# MCXN947_cm33_core0 register map
Vendor: nxp.com; File version: 1.0
CPU: CM33 r2p0, little endian, MPU, FPU, VTOR, 3 interrupt priority bits
Registers are 32-bit, read-write, reset 0x0 unless marked. A register's access mark holds for its fields unless they carry their own. Offsets are from the block's base; [hi:lo] are bit positions; lines under a group give offsets from that group; {n}, {i} and the like mark numbered series.

## FMU0TEST — FlashTest
Base 0x4004E000
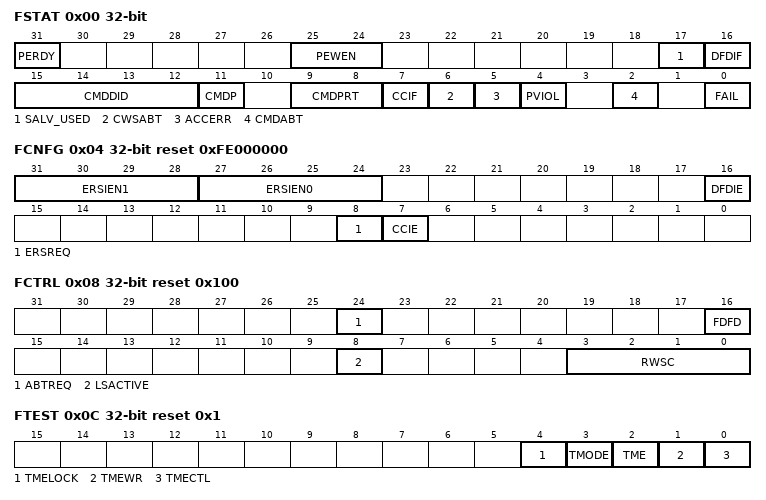
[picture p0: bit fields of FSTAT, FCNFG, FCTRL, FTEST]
0x00 FSTAT — Flash Status Register
  [31] PERDY — Program/Erase Ready Control/Status Flag
    0=zz1 (Program or sector erase command operation is not stalled); 1=zz2 (Program or sector erase command operation is stalled)
  [25:24] PEWEN — Program-Erase Write Enable Control
    0=zz3 (Writes are not enabled); 1=zz4 (Writes are enabled for one flash or IFR phrase (phrase programming, sector erase)); 2=zz5 (Writes are enabled for one flash or IFR page (page programming))
  [17] SALV_USED — Salvage Used for Erase operation
    0=zz7 (Salvage not used during the last operation); 1=zz8 (Salvage used during the last erase operation)
  [16] DFDIF ro — Double Bit Fault Detect Interrupt Flag
    0=zz9 (Double bit fault not detected during a valid flash read access from the FMC); 1=zz10 (Double bit fault detected (or FCTRL[FDFD] is set) during a valid flash read access from the FMC)
  [15:12] CMDDID ro — Command Domain ID
  [11] CMDP ro — Command Protection Status Flag
    0=zz11 (Command protection level and domain ID are stale); 1=zz12 (Command protection level (CMDPRT) and domain ID (CMDDID) are set)
  [9:8] CMDPRT ro — Command Protection Level
    0=zz13 (Secure, normal access); 1=zz14 (Secure, privileged access); 2=zz15 (Nonsecure, normal access); 3=zz16 (Nonsecure, privileged access)
  [7] CCIF write-1-clears — Command Complete Interrupt Flag
    0=zz17 (Flash command or initialization in progress); 1=zz18 (Flash command or initialization has completed)
  [6] CWSABT ro — Command Write Sequence Abort Flag
    0=zz19 (Command write sequence not aborted); 1=zz20 (Command write sequence aborted)
  [5] ACCERR write-1-clears — Command Access Error Flag
    0=zz21 (No access error detected); 1=zz22 (Access error detected)
  [4] PVIOL write-1-clears — Command Protection Violation Flag
    0=zz23 (No protection violation detected); 1=zz24 (Protection violation detected)
  [2] CMDABT ro — Command Abort Flag
    0=zz25 (No command abort detected); 1=zz26 (Command abort detected)
  [0] FAIL — Command Fail Flag
    0=zz27 (Error not detected); 1=zz28 (Error detected)
0x04 FCNFG reset 0xFE000000 — Flash Configuration Register
  [31:28] ERSIEN1 — Erase IFR Sector Enable - Block 1 (for dual block configs)
    0=zz29 (Block 1 IFR Sector X is protected from erase by ERSSCR command); 1=zz30 (Block 1 IFR Sector X is not protected from erase by ERSSCR command)
  [27:24] ERSIEN0 — Erase IFR Sector Enable - Block 0
    0=zz31 (Block 0 IFR Sector X is protected from erase by ERSSCR command); 1=zz32 (Block 0 IFR Sector X is not protected from erase by ERSSCR command)
  [16] DFDIE ro — Double Bit Fault Detect Interrupt Enable
    0=zz33 (Double bit fault detect interrupt disabled); 1=zz34 (Double bit fault detect interrupt enabled; an interrupt request is generated whenever the FSTAT[DFDIF] flag is set)
  [8] ERSREQ ro — Mass Erase (Erase All) Request
    0=zz35 (No request or request complete); 1=zz36 (Request to run the Mass Erase operation)
  [7] CCIE ro — Command Complete Interrupt Enable
    0=zz37 (Command complete interrupt disabled); 1=zz38 (Command complete interrupt enabled. An interrupt request is generated whenever the FSTAT[CCIF] flag is set.)
0x08 FCTRL reset 0x100 — Flash Control Register
  [24] ABTREQ ro — Abort Request
    0=zz39 (No request to abort a command write sequence); 1=zz40 (Request to abort a command write sequence)
  [16] FDFD ro — Force Double Bit Fault Detect
    0=zz41 (FSTAT[DFDIF] sets only if a double bit fault is detected during a valid flash read access from the FMC); 1=zz42 (FSTAT[DFDIF] sets during any valid flash read access from the FMC; an interrupt request is generated if the DFDIE bit is set)
  [8] LSACTIVE — Low Speed Active Mode
    0=zz43 (Full speed active mode requested); 1=zz44 (Low speed active mode requested)
  [3:0] RWSC — Read Wait-State Control
    0=zz45 (no additional wait-states are added (single cycle access)); 1=zz46 (1 additional wait-state is added); {v}=zz{v+45} ({v} additional wait-states are added) (v=2..15)
0x0C FTEST ro reset 0x1 — Flash Test Register
  [4] TMELOCK — Test Mode Entry Lock
    0=zz61 (FTEST register not locked from accepting writes); 1=zz62 (FTEST register locked from accepting writes)
  [3] TMODE — Test Mode Status
    0=zz63 (Test mode not active); 1=zz64 (Test mode active)
  [2] TME — Test Mode Entry
    0=zz65 (Test mode entry not requested); 1=zz66 (Test mode entry requested)
  [1] TMEWR — Test Mode Entry Writable
    0=zz67 (TME bit is not writable); 1=zz68 (TME bit is writable)
  [0] TMECTL — Test Mode Entry Control
    0=zz69 (FTEST register always reads 0 and writes to FTEST are ignored); 1=zz70 (FTEST register is readable and can be written to enable writability of TME)
0x10 FCCOB0 — Flash Command Control 0 Register
  [7:0] CMDCODE — Command code
0x14 FCCOB1 — Flash Command Control 1 Register
  [7:0] CMDOPT — Command options
0x18 FCCOB2 — Flash Command Control 2 Register
  [31:0] CMDADDR — Command starting address
0x1C FCCOB3 — Flash Command Control 3 Register
  [31:0] CMDADDRE — Command ending address
{0x10+4i} FCCOB{i} (i=4..7) — Flash Command Control {i} Register
  [31:0] CMDDATA{i-4} — Command data word {i-4}
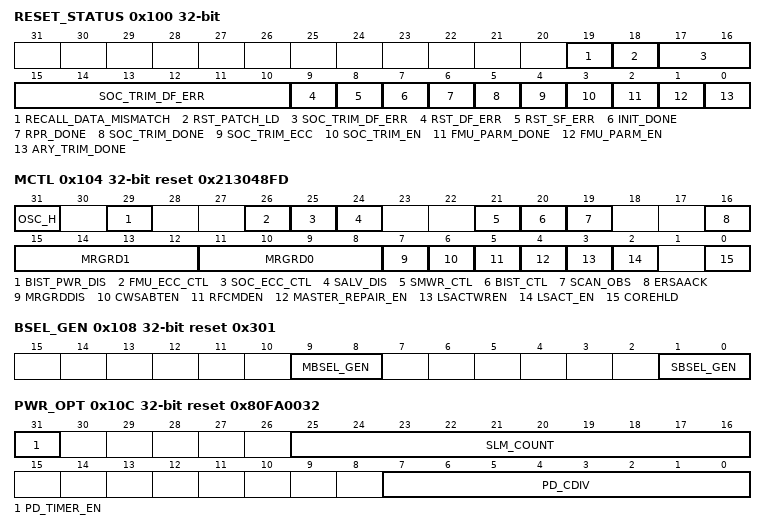
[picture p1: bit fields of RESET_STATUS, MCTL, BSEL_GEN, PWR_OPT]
0x100 RESET_STATUS — FMU Initialization Tracking Register
  [19] RECALL_DATA_MISMATCH
    0=zz71 (Data read towards end of reset matched data read for Recall); 1=zz72 (Data read towards end of reset did not match data read for recall)
  [18] RST_PATCH_LD — Reset Patch Required
    0=zz73 (No patch required to be loaded during reset); 1=zz74 (Patch loaded during reset)
  [17:10] SOC_TRIM_DF_ERR — ECC Double Fault during load of SoC Trim phrases
  [9] RST_DF_ERR — ECC Double Fault during Reset Recovery
    0=zz75 (No double-bit faults detected during initialization); 1=zz76 (Double-bit ECC fault was detected during initialization)
  [8] RST_SF_ERR — ECC Single Fault during Reset Recovery
    0=zz77 (No single-bit faults detected during initialization); 1=zz78 (At least one single ECC fault was detected during initialization)
  [7] INIT_DONE — Initialization Done
    0=zz79 (All initialization steps did not complete); 1=zz80 (All initialization steps completed)
  [6] RPR_DONE — Array Repair Complete
    0=zz81 (Repair registers have not been loaded); 1=zz82 (Repair registers have been loaded)
  [5] SOC_TRIM_DONE — SoC Trim Complete
    0=zz83 (SoC Trim registers have not been updated); 1=zz84 (All SoC Trim registers have been updated)
  [4] SOC_TRIM_ECC — Status of the C0DE_C0DEh check for enabling ECC decoder during reads of SoC trim settings
    0=zz85 (C0DE_C0DEh check failed); 1=zz86 (C0DE_C0DEh check passed)
  [3] SOC_TRIM_EN — Status of the C0DE_C0DEh check to enable loading of the SoC trim settings
    0=zz87 (C0DE_C0DEh check not attempted); 1=zz88 (C0DE_C0DEh check completed)
  [2] FMU_PARM_DONE — FMU Register Load Complete
    0=zz89 (FMU registers have not been loaded); 1=zz90 (FMU registers have been loaded)
  [1] FMU_PARM_EN — Status of the C0DE_C0DEh check to enable loading of the FMU parameters
    0=zz91 (C0DE_C0DEh check not attempted); 1=zz92 (C0DE_C0DEh check completed)
  [0] ARY_TRIM_DONE — Array Trim Complete
    0=zz93 (Recall register load operation has not been completed); 1=zz94 (Recall register load operation has completed)
0x104 MCTL reset 0x213048FD — FMU Control Register
  [31] OSC_H — Oscillator control
    0=zz95 (Use APB clock); 1=zz96 (Use a known fixed-frequency clock, e.g. 12 MHz)
  [29] BIST_PWR_DIS — BIST Power Mode Disable
    0=zz97 (BIST DFT logic has full control of SLM and LVE when BIST is enabled (including during commands)); 1=zz98 (BIST DFT logic has no control of SLM and LVE; power mode RTL is in complete control of SLM and LVE values)
  [26] FMU_ECC_CTL — FMU ECC Control
    0=zz99 (ECC is enabled for FMU program operations); 1=zz100 (ECC is disabled for FMU program operations)
  [25] SOC_ECC_CTL — SOC ECC Control
    0=zz101 (ECC is enabled for SOC read access); 1=zz102 (ECC is disabled for SOC read access)
  [24] SALV_DIS — Salvage Disable
    0=zz103 (Salvage enabled (ECC used during erase verify)); 1=zz104 (Salvage disabled (ECC not used during erase verify))
  [21] SMWR_CTL — SMWR IP Control
    0=zz105 (SMWR IP disabled); 1=zz106 (SMWR IP enabled)
  [20] BIST_CTL — BIST IP Control
    0=zz107 (BIST IP disabled); 1=zz108 (BIST IP enabled)
  [19] SCAN_OBS — Scan Observability Control
    0=zz109 (Normal functional behavior); 1=zz110 (Enables observation of signals that may otherwise be ATPG untestable)
  [16] ERSAACK — Mass Erase (Erase All) Acknowledge
    0=zz111 (Mass Erase operation is not active (operation has completed or has not started)); 1=zz112 (Mass Erase operation is active (controller acknowledges that the soc_ersall_req input is asserted and will continue with the operation))
  [15:12] MRGRD1 — Margin Read Setting for Erase
  [11:8] MRGRD0 — Margin Read Setting for Program
  [7] MRGRDDIS — Margin Read Disable
    0=zz113 (Margin Read Settings are enabled); 1=zz114 (Margin Read Settings are disabled)
  [6] CWSABTEN — Command Write Sequence Abort Enable
    0=zz115 (CWS abort feature is disabled); 1=zz116 (CWS abort feature is enabled)
  [5] RFCMDEN — RF Active Command Enable Control
    0=zz117 (Flash commands blocked (CCIF not writable)); 1=zz118 (Flash commands allowed)
  [4] MASTER_REPAIR_EN — Master Repair Enable
    0=zz119 (Repair disabled); 1=zz120 (Repair enable determined by bit 0 of each REPAIR register)
  [3] LSACTWREN — LSACTIVE Write Enable
    0=zz121 (Unrestricted write access allowed); 1=zz122 (Write access while CMP set must match CMDDID and CMDPRT)
  [2] LSACT_EN — LSACTIVE Feature Enable
    0=zz123 (LSACTIVE feature disabled completely: FCTRL[LSACTIVE] is forced low and no longer writable, LVE cannot assert at the TSMC array interface.); 1=zz124 (LSACTIVE feature fully enabled and controllable by SoC and internal UINT SM.)
  [0] COREHLD — Core Hold
    0=zz125 (CPU access is allowed); 1=zz126 (CPU access must be blocked)
0x108 BSEL_GEN ro reset 0x301 — FMU Block Select Generation Register
  [9:8] MBSEL_GEN — Generated MBSEL
  [1:0] SBSEL_GEN — Generated SBSEL
0x10C PWR_OPT reset 0x80FA0032 — Power Mode Options Register
  [31] PD_TIMER_EN — Power Down BIST Timer Enable
    0=zz127 (BIST timer is not triggered during Power Down recovery); 1=zz128 (BIST timer is triggered during Power Down recovery (default behavior))
  [25:16] SLM_COUNT — Sleep Recovery Timer Count
  [7:0] PD_CDIV — Power Down Clock Divider Setting
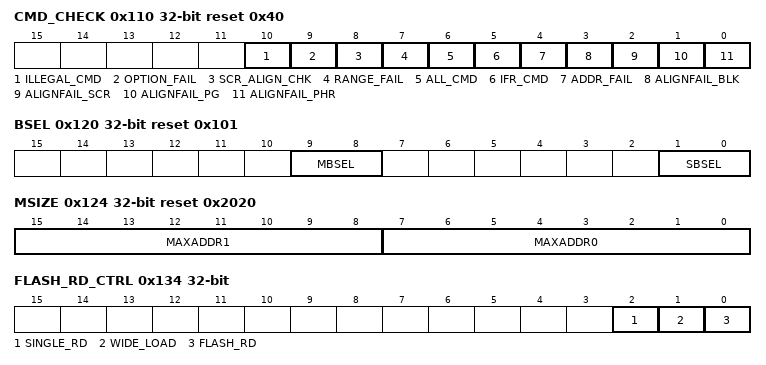
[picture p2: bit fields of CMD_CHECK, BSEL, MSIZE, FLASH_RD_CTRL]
0x110 CMD_CHECK ro reset 0x40 — FMU Command Check Register
  [10] ILLEGAL_CMD — Illegal Command
    0=zz129 (Command is legal); 1=zz130 (Command is illegal)
  [9] OPTION_FAIL — Option Check Fail
    0=zz131 (Option check passes for read command or command is not a read command); 1=zz132 (Option check fails for read command)
  [8] SCR_ALIGN_CHK — Sector Alignment Check
    0=zz133 (No sector alignment check); 1=zz134 (Sector alignment check)
  [7] RANGE_FAIL — Address Range Fail
    0=zz135 (The address range is valid); 1=zz136 (The address range is invalid)
  [6] ALL_CMD — All Blocks Command
    0=zz137 (The command operates on a single flash block); 1=zz138 (The command operates on all flash blocks)
  [5] IFR_CMD — IFR Command
    0=zz139 (The command operates on a main flash address); 1=zz140 (The command operates on an IFR address)
  [4] ADDR_FAIL — Address Fail
    0=zz141 (The address is within the flash or IFR address space); 1=zz142 (The address is outside the flash or IFR address space)
  [3] ALIGNFAIL_BLK — Block Alignment Fail
    0=zz143 (The address is block-aligned); 1=zz144 (The address is not block-aligned)
  [2] ALIGNFAIL_SCR — Sector Alignment Fail
    0=zz145 (The address is sector-aligned); 1=zz146 (The address is not sector-aligned)
  [1] ALIGNFAIL_PG — Page Alignment Fail
    0=zz147 (The address is page-aligned); 1=zz148 (The address is not page-aligned)
  [0] ALIGNFAIL_PHR — Phrase Alignment Fail
    0=zz149 (The address is phrase-aligned); 1=zz150 (The address is not phrase-aligned)
0x120 BSEL reset 0x101 — FMU Block Select Register
  [9:8] MBSEL — Master Block Select
  [1:0] SBSEL — Slave Block Select
0x124 MSIZE reset 0x2020 — FMU Memory Size Register
  [15:8] MAXADDR1 — Size of Flash Block 1
  [7:0] MAXADDR0 — Size of Flash Block 0
0x128 FLASH_RD_ADD — Flash Read Address Register
  [31:0] FLASH_RD_ADD — Flash Read Address
0x130 FLASH_STOP_ADD — Flash Stop Address Register
  [31:0] FLASH_STOP_ADD — Flash Stop Address
0x134 FLASH_RD_CTRL — Flash Read Control Register
  [2] SINGLE_RD — Single Flash Read
    0=zz151 (Normal UINT operation); 1=zz152 (UINT configured for single cycle reads)
  [1] WIDE_LOAD — Wide Load Enable
    0=zz153 (Wide load mode disabled (default)); 1=zz154 (Wide load mode enabled)
  [0] FLASH_RD — Flash Read Enable
    0=zz155 (Manual flash read not enabled.(default)); 1=zz156 (Manual flash read enabled)
0x138 MM_ADDR — Memory Map Address Register
  [31:0] MM_ADDR — Memory Map Address
0x140 MM_WDATA — Memory Map Write Data Register
  [31:0] MM_WDATA — Memory Map Write Data
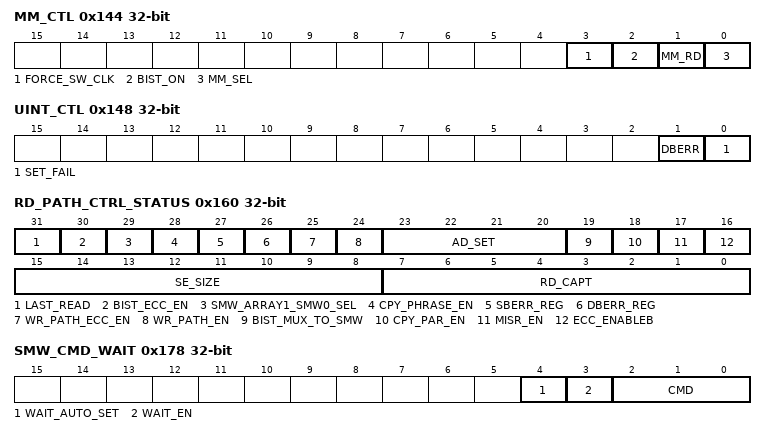
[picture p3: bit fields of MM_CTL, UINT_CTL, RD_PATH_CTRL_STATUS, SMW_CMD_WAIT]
0x144 MM_CTL — Memory Map Control Register
  [3] FORCE_SW_CLK — Force Switch Clock
    0=zz157 (Switch clock not forced on (gated normally)); 1=zz158 (Switch clock forced on)
  [2] BIST_ON
    0=zz159 (BIST enable not forced by user interface); 1=zz160 (BIST enable control by user interface)
  [1] MM_RD — Register R/W Control
    0=zz161 (Write to register); 1=zz162 (Read register)
  [0] MM_SEL — Register Access Enable
0x148 UINT_CTL — User Interface Control Register
  [1] DBERR — Double-Bit ECC Fault Detect
    0=zz163 (No double-bit fault detected during UINT-driven read sequence); 1=zz164 (Double-bit fault detected during UINT-driven read sequence)
  [0] SET_FAIL — Set Fail On Exit
    0=zz165 (FAIL flag should not be set on command exit (no failure detected)); 1=zz166 (FAIL flag should be set on command exit)
{0x14C+4i} RD_DATA{i} (i=0..3) — Read Data {i} Register
  [31:0] RD_DATA{i} — Read Data {i}
0x15C PARITY
  [8:0] PARITY — Read data [136:128]
0x160 RD_PATH_CTRL_STATUS — Read Path Control and Status Register
  [31] LAST_READ
    0=zz167 (Latest read not last in multi-address operation); 1=zz168 (Latest read last in multi-address operation)
  [30] BIST_ECC_EN — BIST ECC Enable
    0=zz169 (ECC correction disabled); 1=zz170 (ECC correction enabled)
  [29] SMW_ARRAY1_SMW0_SEL
    0=zz171 (Select block 0); 1=zz172 (Select block 1)
  [28] CPY_PHRASE_EN — Copy Phrase Enable
    0=zz173 (Copy Flash read data disabled); 1=zz174 (Copy Flash read data enabled)
  [27] SBERR_REG ro — Single-Bit Error
    0=zz175 (Single-bit fault not detected); 1=zz176 (Single-bit fault detected on previous UINT flash read)
  [26] DBERR_REG ro — Double-Bit Error
    0=zz177 (Double-bit fault not detected); 1=zz178 (Double-bit fault detected on previous UINT flash read)
  [25] WR_PATH_ECC_EN — Write Path ECC Enable
    0=zz179 (ECC encoding disabled); 1=zz180 (ECC encoding enabled)
  [24] WR_PATH_EN — Write Path Enable
    0=zz181 (Writes to BIST setting registers driven by MM_WDATA); 1=zz182 (Writes to BIST setting registers driven by SMW_DIN)
  [23:20] AD_SET — Multi-Cycle Address Setup Time
  [19] BIST_MUX_TO_SMW
    0=zz183 (BIST drives fields); 1=zz184 (SMW registers drive fields)
  [18] CPY_PAR_EN — Copy Parity Enable
    0=zz185 (Copy parity disabled); 1=zz186 (Copy parity enabled)
  [17] MISR_EN — MISR Enable
    0=zz187 (MISR option disabled (default)); 1=zz188 (MISR option enabled)
  [16] ECC_ENABLEB — ECC Decoder Control
    0=zz189 (ECC decoder enabled (default)); 1=zz190 (ECC decoder disabled)
  [15:8] SE_SIZE — SE Clock Periods
  [7:0] RD_CAPT — Read Capture Clock Periods
{0x164+4i} SMW_DIN{i} (i=0..3)
0x174 SMW_ADDR — SMW Address Register
  [31:0] SMW_ADDR — SMW Address
0x178 SMW_CMD_WAIT — SMW Command and Wait Register
  [4] WAIT_AUTO_SET — SMW Wait Auto Set
  [3] WAIT_EN — SMW Wait Enable
    0=zz191 (Wait feature disabled); 1=zz192 (Wait feature enabled)
  [2:0] CMD — SMW Command
    0=zz193 (IDLE); 1=zz194 (ABORT); 2=zz195 (SME2 to one-shot mass erase); 3=zz196 (SME3 to sector erase on selected array); 4=zz197 (SMP1 to program phrase or page on selected array with shot disabled on previously programmed bit); 6=zz199 (SMP2 to program phrase or page on selected array to repair cells of weak program after power loss)
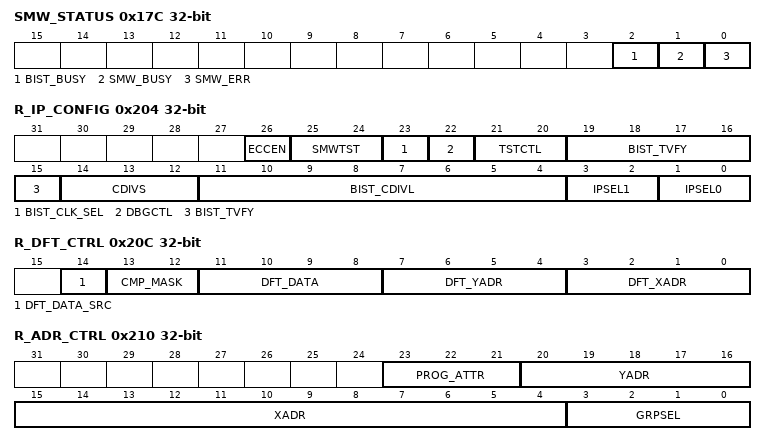
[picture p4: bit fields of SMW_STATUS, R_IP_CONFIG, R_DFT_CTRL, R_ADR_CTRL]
0x17C SMW_STATUS ro
  [2] BIST_BUSY
    0=zz201 (BIST Command not active); 1=zz202 (BIST Command is active)
  [1] SMW_BUSY
    0=zz203 (SMW command not active); 1=zz204 (SMW command is active)
  [0] SMW_ERR — SMW Error
    0=zz205 (Error not detected); 1=zz206 (Error detected)
{0x180+0x10*i} SOCTRIM{i}_0 reset 0xFFFFFFFF (i=0..7) — SoC Trim Phrase {i} Word 0 Register
  [31:0] TRIM{i}_0
{0x184+0x10*i} SOCTRIM{i}_1 reset 0xFFFFFFFF (i=0..7) — SoC Trim Phrase {i} Word 1 Register
  [31:0] TRIM{i}_1
{0x188+0x10*i} SOCTRIM{i}_2 reset 0xFFFFFFFF (i=0..7) — SoC Trim Phrase {i} Word 2 Register
  [31:0] TRIM{i}_2
{0x18C+0x10*i} SOCTRIM{i}_3 reset 0xFFFFFFFF (i=0..7) — SoC Trim Phrase {i} Word 3 Register
  [31:0] TRIM{i}_3
0x204 R_IP_CONFIG — BIST Configuration Register
  [26] ECCEN — BIST ECC Control
    0=zz207 (Default mode (no ECC encode or decode)); 1=zz208 (Enable ECC encode/decode)
  [25:24] SMWTST — SMWR DOUT Function Control
    0=zz209 (Default); 1=zz210 (Enable SMWR self-test mode, DOUT from macro will be forced to all 0); 2=zz211 (Enable SMWR self-test mode, DOUT from macro will be forced to all 1)
  [23] BIST_CLK_SEL — BIST Clock Select
  [22] DBGCTL — Debug feature control
    0=zz213 (Default); 1=zz214 (Enable debug feature to collect failure address and data.)
  [21:20] TSTCTL — BIST self-test control
    0=zz215 (Default, disable both BIST self-test and MISR); 1=zz216 (Enable BIST self-test mode DOUT from macro will be forced to '0', and disable MISR.); 2=zz217 (Enable MISR); 3=zz218 (Enable both BIST self-test mode and MISR)
  [19:15] BIST_TVFY — Timer adjust for verify
  [14:12] CDIVS — Number of clock cycles to generate short pulse
  [11:4] BIST_CDIVL — Clock Divide Scalar for Long Pulse
  [3:2] IPSEL1 — Block 1 Select Control
    0=zz219 (Unselect block 1); 1=zz220 (not used, reserved); 2=zz221 (Enable block 1 test, repair off (default)); 3=zz222 (Enable block 1 test, repair on)
  [1:0] IPSEL0 — Block 0 Select Control
    0=zz223 (Unselect block 0); 1=zz224 (not used, reserved); 2=zz225 (Enable block 0 test, repair off (default)); 3=zz226 (Enable block 0 test, repair on)
0x208 R_TESTCODE — BIST Test Code Register
  [5:0] TESTCODE — Used to store test code information before running TMR-RST/TMRSET BIST command
0x20C R_DFT_CTRL — BIST DFT Control Register
  [14] DFT_DATA_SRC — DFT Data Source
    0=zz227 ({R_DATA_CTRL0,R_DATA_CTRL_EX[2:0],R_DATA_CTRL0,R_DATA_CTRL_EX[2:0],R_DATA_CTRL0,R_DATA_CTRL_EX[2:0],R_DATA_CTRL0} is used); 1=zz228 ({R_DATA_CTRL3,R_DATA_CTRL2_EX[2:0],R_DATA_CTRL2,R_DATA_CTRL1_EX[2:0],R_DATA_CTRL1,R_DATA_CTRL_EX[2:0],R_DATA_CTRL0} is used)
  [13:12] CMP_MASK — Data Compare Mask
    0=zz229 (Expected data is compared to DOUT); 1=zz230 (Expected data (only 0s are considered) are compared to DOUT); 2=zz231 (Expected data (only 1s are considered) are compared to DOUT)
  [11:8] DFT_DATA — DFT Data Pattern
    0=zz232 (CKBD pattern. For READ operations only, compare DOUT with checkerboard data pattern for each read cycle.); 1=zz233 (ICKBD pattern. For READ operations only, compare DOUT with inverse checkerboard data pattern for each read cycle.); 2=zz234 (Diagonal pattern. Used for READ operations only, compare DOUT to diagonal pattern.); 3=zz235 (Fixed data pattern. For READ operations, comparison to DOUT for selected groups; refer to R_ADR_CTRL[GRPSEL] for modules with multiple groups.); 4=zz236 (Random data pattern which will be generated based on the initial seed set in R_DATA; for READ operations, used for DOUT comparison of selected groups. For PROG operations, used to control DIN of selected groups.); 5=zz237 (DOUT based pattern. For READ operations only, DOUT of selected group will be latched in R_DATA. If more than one group is selected in R_ADR_CTRL[GRPSEL], the group with the lower index will be latched.); 6=zz238 (R_DATA based pattern. For READ operations, expected DOUT value of selected groups equals to R_DATA when XADR[0]==YADR[0] or ~R_DATA when XADR[0]!=YADR[0]. For PROG operations, DIN of selected groups equals R_DATA when XADR[0]==YADR[0] or ~R_DATA when XADR[0]!=YADR[0].); 7=zz239 (SCAN-IO pattern. For READ operations, control expected DOUT value of selected groups to SCAN-IO data pattern. For PROG operations, control DIN of selected groups to SCAN-IO data pattern.); 8=zz240 (REPAIR set. For PROG operation to IFR1(7,1) and IFR1(7,2), R_REPAIR0_0 and R_REPAIR0_1 or R_REPAIR1_0 and R_REPAIR1_1 will control DIN. For READ operation on IFR1(7,1) and IFR1(7,2), DOUT will be compared against R_REPAIR0_0 and R_REPAIR0_1 or R_REPAIR1_0 andR_REPAIR1_1. When this option is selected, only one flash block can be selected.); 9=zz241 (REPAIR load. For READ operation only, DOUT from IFR1(7,1) and IFR1(7,2) is loaded to R_REPAIR0 and R_REPAIR1.)
  [7:4] DFT_YADR — DFT YADR Pattern
    0=zz242 (YADR fixed, no change at all); 1=zz243 (YADR for ICKBD. For PROG and READ operations, YADR changed to generate inverse checkerboard pattern.); 2=zz244 (YADR for CKBD. For PROG and READ operations, YADR changed to generate checkerboard pattern.); 3=zz245 (YADR increased by 1. For READ operations, YADR increased by 1 after each read cycle. For PROG operations, YADR increased by 1 after YE falls.); 4=zz246 (YADR increased for diagonal. For PROG-DIAGONAL operation, YADR is increased to create diagonal pattern.); 5=zz247 (YADR inversed. YADR is inversed after reading one word or after programming one word when YE falls.); 6=zz248 (YADR[0] inversed. YADR[0] is inversed after reading one word or after programming one word when YE falls.); 7=zz249 (YADR increased by 1 after last row. For READ operations only, YADR is increased by 1 after XADR reaches last row.); 8=zz250 (YADR decreased by 1. For READ operations only, YADR is decreased by 1 after each read cycle.); 9=zz251 (YADR decreased by 1 after first row. For READ operations only, YADR is decreased by 1 after XADR decreases to 0.)
  [3:0] DFT_XADR — DFT XADR Pattern
    0=zz252 (XADR fixed, no change at all); 1=zz253 (XADR increased by 1 after row. For READ operation, XADR increases by 1 after reading the last word of row. For PROG operation, XADR increases by 1 after NVSTR falls.); 2=zz254 (XADR increased for diagonal. For PROG-DIAGONAL operation, XADR is increased to create diagonal pattern.); 3=zz255 (XADR increased by sector. During ERASE operation, XADR increased by number of rows in a sector when NVSTR falls.); 4=zz256 (XADR inversed. XADR is inversed after reading one word or after programming one row when NVSTR falls.); 5=zz257 (XADR increased by 2 after row. For READ operation, XADR is increased by 2 after reading the last word of a row. For PROG operation, XADR is increased by 2 when NVSTR falls.); 6=zz258 (XADR[0] inversed. XADR[0] is inversed after reading one word or after programming one row when NVSTR falls.); 7=zz259 (XADR increased by 1. For READ operations only, XADR increased by 1 after each read cycle.); 8=zz260 (XADR decreased by 1 after row. For READ operations only, XADR is decreased by 1 after YADR decreases to 0.); 9=zz261 (XADR decreased by 1. For READ operations only, XADR is decreased by 1 after each read cycle.)
0x210 R_ADR_CTRL — BIST Address Control Register
  [23:21] PROG_ATTR — Program Attribute
    0=zz262 (One YE pulse will program one data slice group); 1=zz263 (One YE pulse will program two data slice groups); 2=zz264 (One YE pulse will program three data slice groups (reserved)); 3=zz265 (One YE pulse will program four data slice groups); 4=zz266 (One YE pulse will program five data slice groups (reserved)); 5=zz267 (One YE pulse will program six data slice groups (reserved)); 6=zz268 (One YE pulse will program seven data slice groups (reserved)); 7=zz269 (One YE pulse will program eight data slice groups (reserved))
  [20:16] YADR — BIST YADR
  [15:4] XADR — BIST XADR
  [3:0] GRPSEL — Data Group Select
    0=zz270 (Select no data); 1=zz271 (Select data slice [34:0]); 2=zz272 (Select data slice [69:35]); 4=zz273 (Select data slice [104:70]); 8=zz274 (Select data slice [136:105]); 15=zz275 (Select data [136:0])
0x214 R_DATA_CTRL0 — BIST Data Control 0 Register
  [31:0] DATA0 — BIST Data 0 Low
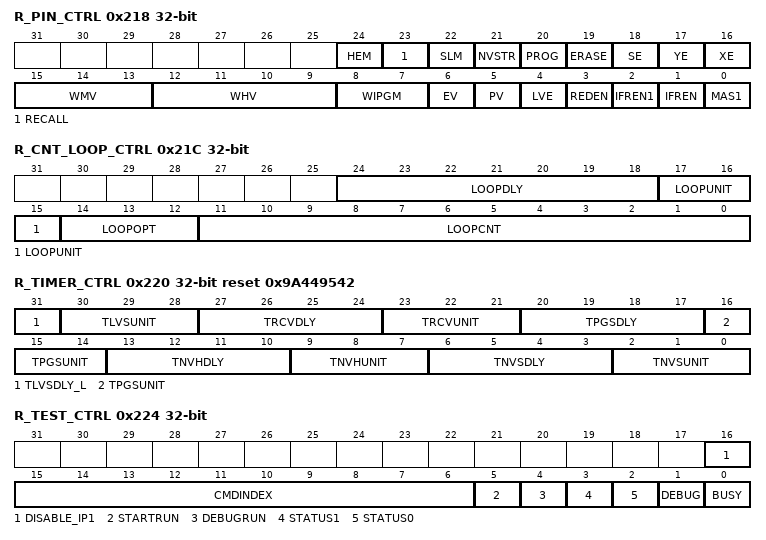
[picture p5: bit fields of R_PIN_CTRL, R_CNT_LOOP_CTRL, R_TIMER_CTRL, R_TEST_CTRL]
0x218 R_PIN_CTRL — BIST Pin Control Register
  [24] HEM — HEM Control
  [23] RECALL — Recall Trim Code
  [22] SLM — Sleep Mode Enable
  [21] NVSTR — NVM Store
  [20] PROG — Program Mode
  [19] ERASE — Erase Mode
  [18] SE — Sense Amp Enable
  [17] YE — Y Address Enable
  [16] XE — X Address Enable
  [15:13] WMV — Medium Voltage Level
  [12:9] WHV — High Voltage Level
  [8:7] WIPGM — Program Current
  [6] EV — Erase Verify Enable
  [5] PV — Program Verify Enable
  [4] LVE — Low Voltage Enable
  [3] REDEN — Redundancy Block Enable
  [2] IFREN1 — IFR1 Enable
  [1] IFREN — IFR Enable
  [0] MAS1 — Mass Erase
0x21C R_CNT_LOOP_CTRL — BIST Loop Count Control Register
  [24:18] LOOPDLY — Loop Time Delay Scalar
  [17:15] LOOPUNIT — Loop Time Unit
    0=zz276 (Clock cycles); 1=zz277 (0.5 usec); 2=zz278 (1 usec); 3=zz279 (10 usec); 4=zz280 (100 usec); 5=zz281 (1 msec); 6=zz282 (10 msec); 7=zz283 (100 msec)
  [14:12] LOOPOPT — Loop Option
    0=zz284 (Loop is disabled; selected BIST operation is run once); 1=zz285 (Loop is enabled; XADR increments by 1 XADR increments by 1 for each new loop. Stops when total loop count meets LOOPCNT+1.); 2=zz286 (Loop is enabled; YADR increments by 1 YADR increments by 1 for each new loop. Stops when total loop count meets LOOPCNT+1.); 3=zz287 (Loop is enabled; XADR increments by 2 XADR increments by 2 for each new loop. Stops when total loop count meets LOOPCNT+1.); 4=zz288 (Loop is enabled; XADR increments by sector XADR increments by 16 for each new loop. Stops when total loop count meets LOOPCNT+1.)
  [11:0] LOOPCNT — Loop Count Control
0x220 R_TIMER_CTRL reset 0x9A449542 — BIST Timer Control Register
  [31] TLVSDLY_L — Tlvs Time Delay Scalar Low
  [30:28] TLVSUNIT — Tlvs Time Unit
    0=zz289 (Clock cycles); 1=zz290 (0.5 usec); 2=zz291 (1 usec); 3=zz292 (10 usec); 4=zz293 (100 usec); 5=zz294 (1 msec); 6=zz295 (10 msec); 7=zz296 (100 msec)
  [27:24] TRCVDLY — Trcv Time Delay Scalar
  [23:21] TRCVUNIT — Trcv Time Unit
    0=zz297 (Clock cycles); 1=zz298 (0.5 usec); 2=zz299 (1 usec); 3=zz300 (10 usec); 4=zz301 (100 usec); 5=zz302 (1 msec); 6=zz303 (10 msec); 7=zz304 (100 msec)
  [20:17] TPGSDLY — Tpgs Time Delay Scalar
  [16:14] TPGSUNIT — Tpgs Time Unit
    0=zz305 (Clock cycles); 1=zz306 (0.5 usec); 2=zz307 (1 usec); 3=zz308 (10 usec); 4=zz309 (100 usec); 5=zz310 (1 msec); 6=zz311 (10 msec); 7=zz312 (100 msec)
  [13:10] TNVHDLY — Tnvh Time Delay Scalar
  [9:7] TNVHUNIT — Tnvh Time Unit
    0=zz313 (Clock cycles); 1=zz314 (0.5 usec); 2=zz315 (1 usec); 3=zz316 (10 usec); 4=zz317 (100 usec); 5=zz318 (1 msec); 6=zz319 (10 msec); 7=zz320 (100 msec)
  [6:3] TNVSDLY — Tnvs Time Delay Scalar
  [2:0] TNVSUNIT — Tnvs Time Unit
    0=zz321 (Clock cycles); 1=zz322 (0.5 usec); 2=zz323 (1 usec); 3=zz324 (10 usec); 4=zz325 (100 usec); 5=zz326 (1 msec); 6=zz327 (10 msec); 7=zz328 (100 msec)
0x224 R_TEST_CTRL — BIST Test Control Register
  [16] DISABLE_IP1 — BIST Disable IP1
  [15:6] CMDINDEX — BIST Command Index (code)
  [5] STARTRUN — Run New BIST Operation
  [4] DEBUGRUN — BIST Continue Debug Run
  [3] STATUS1 ro — BIST status 1
    0=zz329 (BIST test passed on flash block 1); 1=zz330 (BIST test failed on flash block 1)
  [2] STATUS0 ro — BIST Status 0
    0=zz331 (BIST test passed on flash block 0); 1=zz332 (BIST test failed on flash block 0)
  [1] DEBUG ro — BIST Debug Status
  [0] BUSY ro — BIST Busy Status
    0=zz333 (BIST is idle); 1=zz334 (BIST is busy)
0x228 R_ABORT_LOOP — BIST Abort Loop Register
  [0] ABORT_LOOP
    0=zz335 (No effect); 1=zz336 (Abort BIST loop commands and force the loop counter to return to 0x0)
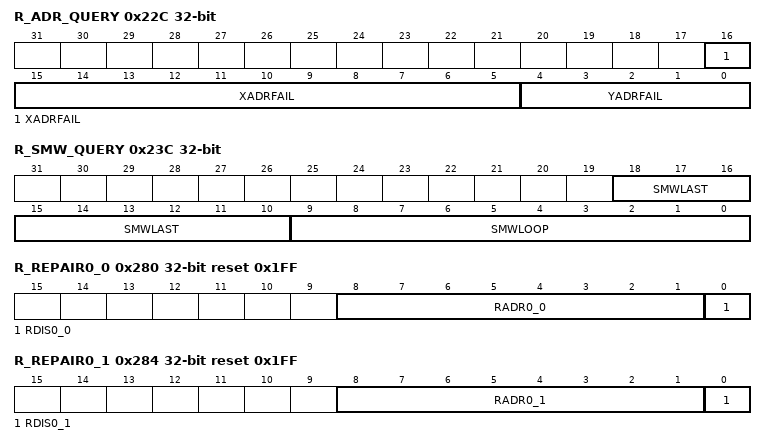
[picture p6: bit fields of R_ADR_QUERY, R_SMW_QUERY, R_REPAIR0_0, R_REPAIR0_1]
0x22C R_ADR_QUERY ro — BIST Address Query Register
  [16:5] XADRFAIL — Failing XADR
  [4:0] YADRFAIL — Failing YADR
0x230 R_DOUT_QUERY0 ro — BIST DOUT Query 0 Register
  [31:0] DOUTFAIL — Failing DOUT Low
0x23C R_SMW_QUERY ro — BIST SMW Query Register
  [18:10] SMWLAST — SMW Last Voltage Setting
  [9:0] SMWLOOP — SMW Total Loop Count
0x240 R_SMW_SETTING0 reset 0xF0B4000 — BIST SMW Setting 0 Register
  [30:0] SMWPARM0 — SMW Parameter Set 0
0x244 R_SMW_SETTING1 reset 0x315CE2A — BIST SMW Setting 1 Register
  [27:0] SMWPARM1 — SMW Parameter Set 1
0x248 R_SMP_WHV0 reset 0x77777765 — BIST SMP WHV Setting 0 Register
  [31:0] SMPWHV0 — SMP WHV Parameter Set 0
0x24C R_SMP_WHV1 reset 0x77777777 — BIST SMP WHV Setting 1 Register
  [31:0] SMPWHV1 — SMP WHV Parameter Set 1
0x250 R_SME_WHV0 reset 0xCCBA9876 — BIST SME WHV Setting 0 Register
  [31:0] SMEWHV0 — SME WHV Parameter Set 0
0x254 R_SME_WHV1 reset 0xCCCCCCCC — BIST SME WHV Setting 1 Register
  [31:0] SMEWHV1 — SME WHV Parameter Set 1
0x258 R_SMW_SETTING2 reset 0xA80151 — BIST SMW Setting 2 Register
  [28:0] SMWPARM2 — SMW Parameter Set 2
0x25C R_D_MISR0 ro — BIST DIN MISR 0 Register
  [31:0] DATASIG0 — Data Signature
0x260 R_A_MISR0 ro — BIST Address MISR 0 Register
  [31:0] ADRSIG0 — Address Signature
0x264 R_C_MISR0 ro — BIST Control MISR 0 Register
  [31:0] CTRLSIG0 — Control Signature
0x268 R_SMW_SETTING3 reset 0x1BE00 — BIST SMW Setting 3 Register
  [16:0] SMWPARM3 — SMW Parameter Set 3
{0x268+4i} R_DATA_CTRL{i} (i=1..3) — BIST Data Control {i} Register
  [31:0] DATA{i} — BIST Data {i} Low
0x280 R_REPAIR0_0 ro reset 0x1FF — BIST Repair 0 for Block 0 Register
  [8:1] RADR0_0 — XADR for Repair 0 in Block 0
  [0] RDIS0_0 — Control Repair 0 in Block 0.
    0=zz337 (Repair address is valid); 1=zz338 (Repair address is not valid)
0x284 R_REPAIR0_1 ro reset 0x1FF — BIST Repair 1 Block 0 Register
  [8:1] RADR0_1 — XADR for Repair 1 in Block 0.
  [0] RDIS0_1 — Control Repair 1 in Block 0.
    0=zz339 (Repair address is valid); 1=zz340 (Repair address is not valid)
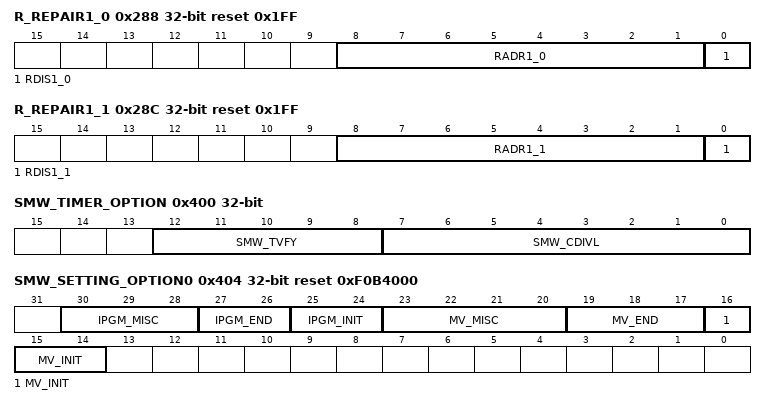
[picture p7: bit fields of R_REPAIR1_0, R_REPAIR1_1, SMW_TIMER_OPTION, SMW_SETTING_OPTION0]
0x288 R_REPAIR1_0 ro reset 0x1FF — BIST Repair 0 Block 1 Register
  [8:1] RADR1_0 — XADR for Repair 0 in Block 1.
  [0] RDIS1_0 — Control Repair 0 in Block 1.
    0=zz341 (Repair address is valid); 1=zz342 (Repair address is not valid)
0x28C R_REPAIR1_1 ro reset 0x1FF — BIST Repair 1 Block 1 Register
  [8:1] RADR1_1 — XADR for Repair 1 in Block 1.
  [0] RDIS1_1 — Control Repair 1 in Block 1.
    0=zz343 (Repair address is valid); 1=zz344 (Repair address is not valid)
0x314 R_DATA_CTRL0_EX — BIST Data Control 0 Extension Register
  [2:0] DATA0X — BIST Data 0 High
0x320 R_TIMER_CTRL_EX reset 0x1 — BIST Timer Control Extension Register
  [2:0] TLVSDLY_H — Tlvs Time Delay Scalar High
0x330 R_DOUT_QUERY1 ro — BIST DOUT Query 1 Register
  [2:0] DOUT — Failing DOUT High
0x35C R_D_MISR1 ro — BIST DIN MISR 1 Register
  [7:0] DATASIG1 — MISR Data Signature High
0x360 R_A_MISR1 ro — BIST Address MISR 1 Register
  [7:0] ADRSIG1 — MISR Address Signature High
0x364 R_C_MISR1 ro — BIST Control MISR 1 Register
  [7:0] CTRLSIG1 — MISR Control Signature High
{0x368+4i} R_DATA_CTRL{i}_EX (i=1..3) — BIST Data Control {i} Extension Register
  [2:0] DATA{i}X — BIST Data {i} High
0x400 SMW_TIMER_OPTION
  [12:8] SMW_TVFY — Timer Adjust for Verify
  [7:0] SMW_CDIVL — Clock Divide Scalar for Long Pulse
0x404 SMW_SETTING_OPTION0 reset 0xF0B4000
  [30:28] IPGM_MISC — Program Current Control Misc
  [27:26] IPGM_END — Program Current Control Final
  [25:24] IPGM_INIT — Program Current Control Initial
  [23:20] MV_MISC — Medium Voltage Control Misc
  [19:17] MV_END — Medium Voltage Level Select Final
  [16:14] MV_INIT — Medium Voltage Level Select Initial
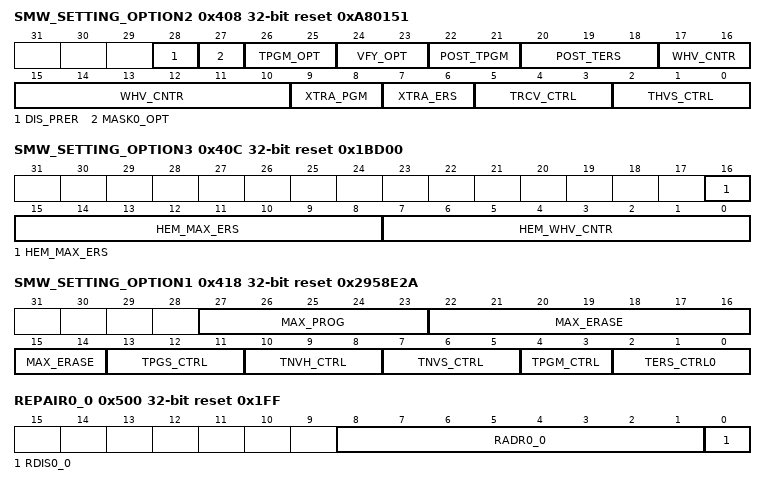
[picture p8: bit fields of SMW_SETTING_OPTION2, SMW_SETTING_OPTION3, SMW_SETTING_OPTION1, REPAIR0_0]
0x408 SMW_SETTING_OPTION2 reset 0xA80151
  [28] DIS_PRER — Disable pre-PV Read before First Program Shot
    0=zz345 (Enable pre-PV read before first program shot); 1=zz346 (Disable pre-PV read before first program shot)
  [27] MASK0_OPT
    0=zz347 (Mask programmed bits passing PV until extra shot); 1=zz348 (Always program bits even if they pass PV)
  [26:25] TPGM_OPT — Tpgm Option
    0=zz349 (Fixed Tpgm for all shots, except post shot); 1=zz350 (Increase Tpgm option by 1 for each loop until Tpgm reaches 4 usec); 2=zz351 (Increase Tpgm option by 1 for each loop until Tpgm reaches 8 usec); 3=zz352 (Unused)
  [24:23] VFY_OPT — Verify Option
    0=zz353 (Skip verify for post shot only, verify for all other shots); 1=zz354 (Skip verify for the 1st and post shots); 2=zz355 (Skip the 1st, 2nd, and post shots); 3=zz356 (Skip verify for all shots)
  [22:21] POST_TPGM — Post Tpgm Time
    0=zz357 (1 usec); 1=zz358 (2 usec); 2=zz359 (4 usec); 3=zz360 (8 usec)
  [20:18] POST_TERS — Post Ters Time
    0=zz361 (50 usec); 1=zz362 (100 usec); 2=zz363 (200 usec); 3=zz364 (300 usec); 4=zz365 (500 usec); 5=zz366 (1 msec); 6=zz367 (1.5 msec); 7=zz368 (2 msec)
  [17:10] WHV_CNTR — WHV Counter
  [9:8] XTRA_PGM — Number of Post Shots for SMP
  [7:6] XTRA_ERS — Number of Post Shots for SME
  [5:3] TRCV_CTRL — Trcv Control
  [2:0] THVS_CTRL — Thvs control
0x40C SMW_SETTING_OPTION3 reset 0x1BD00
  [16:8] HEM_MAX_ERS — HEM Max Erase Shot Count
  [7:0] HEM_WHV_CNTR — WHV_COUNTER for HEM-erase Cycle
0x410 SMW_SMP_WHV_OPTION0 reset 0x77777765
  [31:0] SMP_WHV_OPT0 — Smart Program WHV Option Low
0x414 SMW_SME_WHV_OPTION0 reset 0xCCBA9876
  [31:0] SME_WHV_OPT0 — Smart Erase WHV Option Low
0x418 SMW_SETTING_OPTION1 reset 0x2958E2A
  [27:23] MAX_PROG — Number of Program Shots
  [22:14] MAX_ERASE — Number of Erase Shots
  [13:11] TPGS_CTRL — Tpgs Control
    {v}=zz{v+369} ({v+1} usec) (v=0..7)
  [10:8] TNVH_CTRL — Tnvh Control
    0=zz377 (2 usec); 1=zz378 (2.5 usec); 2=zz379 (3 usec); 3=zz380 (3.5 usec); 4=zz381 (4 usec); 5=zz382 (4.5 usec); 6=zz383 (5 usec); 7=zz384 (5.5 usec)
  [7:5] TNVS_CTRL — Tnvs Control
    0=zz385 (5 usec); 1=zz386 (8 usec); 2=zz387 (11 usec); 3=zz388 (14 usec); 4=zz389 (17 usec); 5=zz390 (20 usec); 6=zz391 (23 usec); 7=zz392 (26 usec)
  [4:3] TPGM_CTRL — Tpgm Control
    0=zz393 (1 usec); 1=zz394 (2 usec); 2=zz395 (4 usec); 3=zz396 (8 usec)
  [2:0] TERS_CTRL0 — Ters Control
    0=zz397 (50 usec); 1=zz398 (100 usec); 2=zz399 (200 usec); 3=zz400 (300 usec); 4=zz401 (500 usec); 5=zz402 (1 msec); 6=zz403 (1.5 msec); 7=zz404 (2 msec)
0x41C SMW_SMP_WHV_OPTION1 reset 0x77777777
  [31:0] SMP_WHV_OPT1 — Smart Program WHV Option High
0x420 SMW_SME_WHV_OPTION1 reset 0xCCCCCCCC
  [31:0] SME_WHV_OPT1 — Smart Erase WHV Option High
0x500 REPAIR0_0 reset 0x1FF — FMU Repair 0 Block 0 Register
  [8:1] RADR0_0
  [0] RDIS0_0
    0=zz405 (Repair address is valid); 1=zz406 (Repair address is not valid)
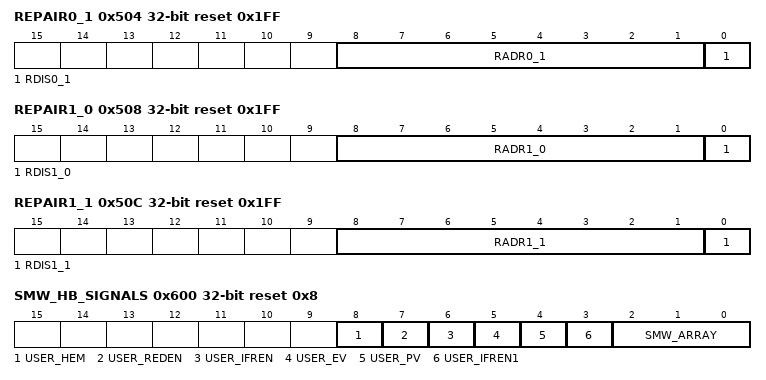
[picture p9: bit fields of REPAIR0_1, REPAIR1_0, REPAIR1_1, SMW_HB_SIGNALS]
0x504 REPAIR0_1 reset 0x1FF — FMU Repair 1 Block 0 Register
  [8:1] RADR0_1
  [0] RDIS0_1
    0=zz407 (Repair address is valid); 1=zz408 (Repair address is not valid)
0x508 REPAIR1_0 reset 0x1FF — FMU Repair 0 Block 1 Register
  [8:1] RADR1_0
  [0] RDIS1_0
    0=zz409 (Repair address is valid); 1=zz410 (Repair address is not valid)
0x50C REPAIR1_1 reset 0x1FF — FMU Repair 1 Block 1 Register
  [8:1] RADR1_1
  [0] RDIS1_1
    0=zz411 (Repair address is valid); 1=zz412 (Repair address is not valid)
0x600 SMW_HB_SIGNALS reset 0x8
  [8] USER_HEM — High Endurance Enable
    0=zz413 (HEM input to SMW / BIST PIN_CTRL[24] is driven LOW); 1=zz414 (HEM input to SMW / BIST PIN_CTRL[24] is driven HIGH)
  [7] USER_REDEN — Repair Read Enable
    0=zz415 (REDEN input to the flash array is driven LOW); 1=zz416 (REDEN input to the flash array is driven HIGH)
  [6] USER_IFREN — IFR Enable
    0=zz417 (IFREN input to the flash array is driven LOW); 1=zz418 (IFREN input to the flash array is driven HIGH)
  [5] USER_EV — Erase Verify
    0=zz419 (EV input to the flash array is driven LOW); 1=zz420 (EV input to the flash array is driven HIGH)
  [4] USER_PV — Program Verify
    0=zz421 (PV input to the flash array is driven LOW); 1=zz422 (PV input to the flash array is driven HIGH)
  [3] USER_IFREN1 — IFR1 Enable
    0=zz423 (IFREN1 input to the flash array is driven LOW); 1=zz424 (IFREN1 input to the flash array is driven HIGH)
  [2:0] SMW_ARRAY — SMW Region Select
    0=zz425 (Main array); 1=zz426 (IFR space only or main (and REDEN space) with IFR space for mass erase); 2=zz427 (IFR1 space); 4=zz428 (REDEN space)
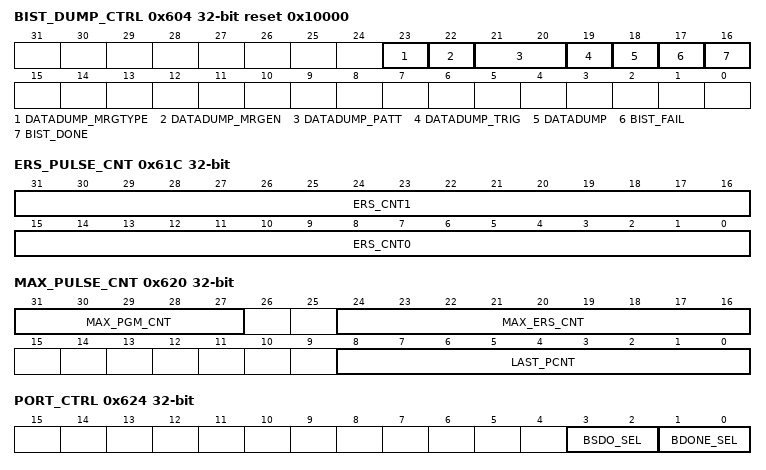
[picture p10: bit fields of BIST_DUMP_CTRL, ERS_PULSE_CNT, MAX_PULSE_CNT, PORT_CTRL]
0x604 BIST_DUMP_CTRL reset 0x10000 — BIST Datadump Control Register
  [23] DATADUMP_MRGTYPE — Data Dump Margin Type
    0=zz429 (DIN method used); 1=zz430 (TM method used)
  [22] DATADUMP_MRGEN — Data Dump Margin Enable
    0=zz431 (Normal read pulse shape); 1=zz432 (Margin read pulse shape)
  [21:20] DATADUMP_PATT — Data Dump Pattern Select
    0=zz433 (All ones); 1=zz434 (All zeroes); 2=zz435 (Checkerboard); 3=zz436 (Inverse checkerboard)
  [19] DATADUMP_TRIG — Data Dump Trigger
  [18] DATADUMP — Data Dump Enable
  [17] BIST_FAIL
    0=zz437 (The last BIST operation completed successfully (or could not fail)); 1=zz438 (The last BIST operation failed)
  [16] BIST_DONE
    0=zz439 (The BIST (or data dump) is running); 1=zz440 (The BIST (or data dump) has completed)
0x60C ATX_PIN_CTRL — ATX Pin Control Register
  [7:0] TM_TO_ATX
    1=zz441 (TM[0] to ATX0); 2=zz442 (TM[1] to ATX0); 4=zz443 (TM[2] to ATX0); 8=zz444 (TM[3] to ATX0); 16=zz445 (TM[0] to ATX1); 32=zz446 (TM[1] to ATX1); 64=zz447 (TM[2] to ATX1); 128=zz448 (TM[3] to ATX1)
0x610 FAILCNT — Fail Count Register
  [31:0] FAILCNT — Fail Count
0x614 PGM_PULSE_CNT0 — Block 0 Program Pulse Count Register
  [31:0] PGM_CNT0 — Program Pulse Count
0x618 PGM_PULSE_CNT1 — Block 1 Program Pulse Count Register
  [31:0] PGM_CNT1 — Program Pulse Count
0x61C ERS_PULSE_CNT — Erase Pulse Count Register
  [31:16] ERS_CNT1 — Block 1 Erase Pulse Count
  [15:0] ERS_CNT0 — Block 0 Erase Pulse Count
0x620 MAX_PULSE_CNT — Maximum Pulse Count Register
  [31:27] MAX_PGM_CNT — Maximum Program Pulse Count
  [24:16] MAX_ERS_CNT — Maximum Erase Pulse Count
  [8:0] LAST_PCNT — Last SMW Operation's Pulse Count
0x624 PORT_CTRL — Port Control Register
  [3:2] BSDO_SEL — BIST Serial Data Output Select
    0=zz449 (Select internal bist_sdo signal from current module instantiation); 1=zz450 (Select ipt_bist_done signal from current module instantiation); 2=zz451 (Select ipt_bist_sdo signal from other module instantiation); 3=zz452 (Select ipt_bist_done signal from other module instantiation)
  [1:0] BDONE_SEL — BIST Done Select
    0=zz453 (Select internal bist_done signal from current module instantiation); 1=zz454 (Select ipt_bist_fail signal from current module instantiation); 2=zz455 (Select ipt_bist_done signal from other module instantiation); 3=zz456 (Select AND of internal bist_done signal from current module instantiation with ipt_bist_done signal from other module instantiation)
